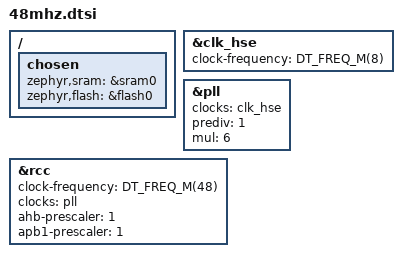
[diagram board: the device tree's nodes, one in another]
/*
 * Copyright (c) 2025 TiaC Systems
 * SPDX-License-Identifier: Apache-2.0
 */

#include <freq.h>

/ {
	chosen {
		zephyr,sram = &sram0;
		zephyr,flash = &flash0;
	};
};

&clk_hse {
	status = "okay";
	clock-frequency = <DT_FREQ_M(8)>;
};

&pll {
	status = "okay";
	clocks = <&clk_hse>;
	prediv = <1>;
	mul = <6>;
};

&rcc {
	status = "okay";
	clock-frequency = <DT_FREQ_M(48)>;
	clocks = <&pll>;
	ahb-prescaler = <1>;
	apb1-prescaler = <1>;
	/* usbpre not set: USB clock = 48 / 1: 48MHz */
};
